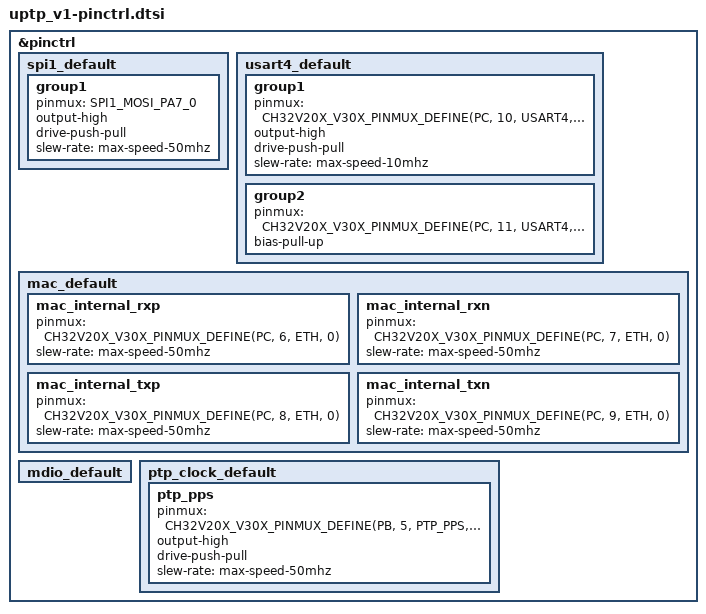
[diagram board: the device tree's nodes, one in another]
/*
 * Copyright (c) 2025 James Bennion-Pedley
 * SPDX-License-Identifier: Apache-2.0
 */

#include <zephyr/dt-bindings/pinctrl/ch32v20x_30x-pinctrl.h>

&pinctrl {
	spi1_default: spi1_default {
		group1 {
			pinmux = <SPI1_MOSI_PA7_0>;
			output-high;
			drive-push-pull;
			slew-rate = "max-speed-50mhz";
		};
	};

	usart4_default: usart4_default {
		group1 {
			pinmux = <CH32V20X_V30X_PINMUX_DEFINE(PC, 10, USART4, 0)>;
			output-high;
			drive-push-pull;
			slew-rate = "max-speed-10mhz";
		};

		group2 {
			pinmux = <CH32V20X_V30X_PINMUX_DEFINE(PC, 11, USART4, 0)>;
			bias-pull-up;
		};
	};

	mac_default: mac_default {
		mac_internal_rxp {
			pinmux = <CH32V20X_V30X_PINMUX_DEFINE(PC, 6, ETH, 0)>;
			slew-rate = "max-speed-50mhz";
		};

		mac_internal_rxn {
			pinmux = <CH32V20X_V30X_PINMUX_DEFINE(PC, 7, ETH, 0)>;
			slew-rate = "max-speed-50mhz";
		};

		mac_internal_txp {
			pinmux = <CH32V20X_V30X_PINMUX_DEFINE(PC, 8, ETH, 0)>;
			slew-rate = "max-speed-50mhz";
		};

		mac_internal_txn {
			pinmux = <CH32V20X_V30X_PINMUX_DEFINE(PC, 9, ETH, 0)>;
			slew-rate = "max-speed-50mhz";
		};
	};

	mdio_default: mdio_default {
		/* No MDIO pinmux required for internal PHY */
	};

	ptp_clock_default: ptp_clock_default {
		ptp_pps {
			pinmux = <CH32V20X_V30X_PINMUX_DEFINE(PB, 5, PTP_PPS, 1)>;
			/* pinmux = <CH32V20X_V30X_PINMUX_DEFINE(PB, 5, TIM10, 1)>; */
			output-high;
			drive-push-pull;
			slew-rate = "max-speed-50mhz";
		};
	};
};
